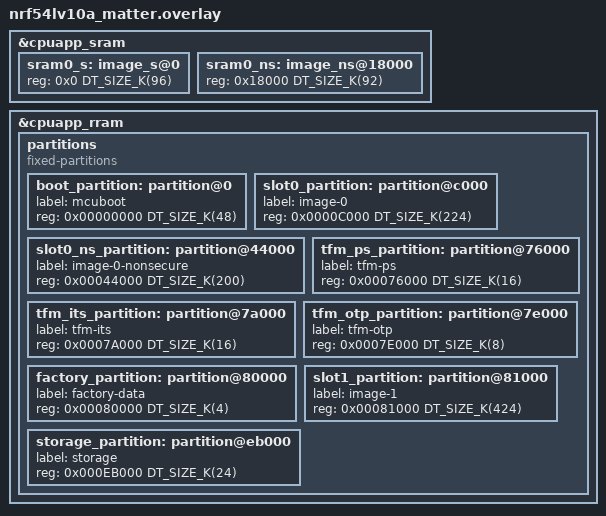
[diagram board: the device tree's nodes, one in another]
/*
 * Copyright (c) 2026 Nordic Semiconductor ASA
 *
 * SPDX-License-Identifier: LicenseRef-Nordic-5-Clause
 */

/*
 * Matter-optimized TF-M partition layout for nRF54LV10A
 *
 * nRF54LV10A has 1012 kB of RRAM and 192 kB of SRAM.
 * TrustZone flash region alignment: 4 kB (MPC-based)
 * TrustZone RAM region alignment:   4 kB
 * RRAM erase-block-size:            4 kB
 *
 * Matter on the nRF54LV10A is very tight — the Matter stack alone
 * needs ~300-400 kB, TF-M full profile ~256 kB, and MCUboot ~48 kB.
 * This layout prioritizes the primary image at the expense of the
 * secondary DFU slot. External flash is strongly recommended for
 * the secondary slot if available.
 *
 * Suitable for: cost-optimized Matter devices (light bulbs, sensors)
 */

&cpuapp_sram {
	sram0_s: image_s@0 {
		#address-cells = <1>;
		#size-cells = <1>;
		reg = <0x0 DT_SIZE_K(96)>;
		ranges = <0x0 0x0 DT_SIZE_K(96)>;
	};

	/* 92 kB NS — 4 kB unused at top */
	sram0_ns: image_ns@18000 {
		#address-cells = <1>;
		#size-cells = <1>;
		reg = <0x18000 DT_SIZE_K(92)>;
		ranges = <0x0 0x18000 DT_SIZE_K(92)>;
	};
};

&cpuapp_rram {
	partitions {
		compatible = "fixed-partitions";
		#address-cells = <1>;
		#size-cells = <1>;

		/*
		 * Flash layout (all addresses 4 kB aligned):
		 *
		 * 0x00000000  MCUboot bootloader        (48 kB)
		 * 0x0000C000  Primary slot:
		 *   0x0000C000  TF-M secure image       (224 kB)
		 *   0x00044000  Non-secure Matter app    (200 kB)
		 * 0x00076000  TF-M PS                    (16 kB)
		 * 0x0007A000  TF-M ITS                   (16 kB)
		 * 0x0007E000  TF-M OTP / NV counters      (8 kB)
		 * 0x00080000  Factory data                (4 kB)
		 * 0x00081000  Secondary slot            (424 kB)
		 * 0x000EB000  Non-secure storage         (24 kB)
		 *
		 * Primary = 224 + 200 = 424 kB = Secondary
		 * Total: 48 + 424 + 16 + 16 + 8 + 4 + 424 + 24 = 964 kB
		 *
		 * WARNING: 200 kB NS may be tight for a full Matter
		 * application. Consider external flash for the secondary
		 * slot to enlarge the NS partition.
		 */

		boot_partition: partition@0 {
			label = "mcuboot";
			reg = <0x00000000 DT_SIZE_K(48)>;
		};

		slot0_partition: partition@c000 {
			label = "image-0";
			reg = <0x0000C000 DT_SIZE_K(224)>;
		};

		slot0_ns_partition: partition@44000 {
			label = "image-0-nonsecure";
			reg = <0x00044000 DT_SIZE_K(200)>;
		};

		tfm_ps_partition: partition@76000 {
			label = "tfm-ps";
			reg = <0x00076000 DT_SIZE_K(16)>;
		};

		tfm_its_partition: partition@7a000 {
			label = "tfm-its";
			reg = <0x0007A000 DT_SIZE_K(16)>;
		};

		tfm_otp_partition: partition@7e000 {
			label = "tfm-otp";
			reg = <0x0007E000 DT_SIZE_K(8)>;
		};

		factory_partition: partition@80000 {
			label = "factory-data";
			reg = <0x00080000 DT_SIZE_K(4)>;
		};

		slot1_partition: partition@81000 {
			label = "image-1";
			reg = <0x00081000 DT_SIZE_K(424)>;
		};

		storage_partition: partition@eb000 {
			label = "storage";
			reg = <0x000EB000 DT_SIZE_K(24)>;
		};
	};
};
